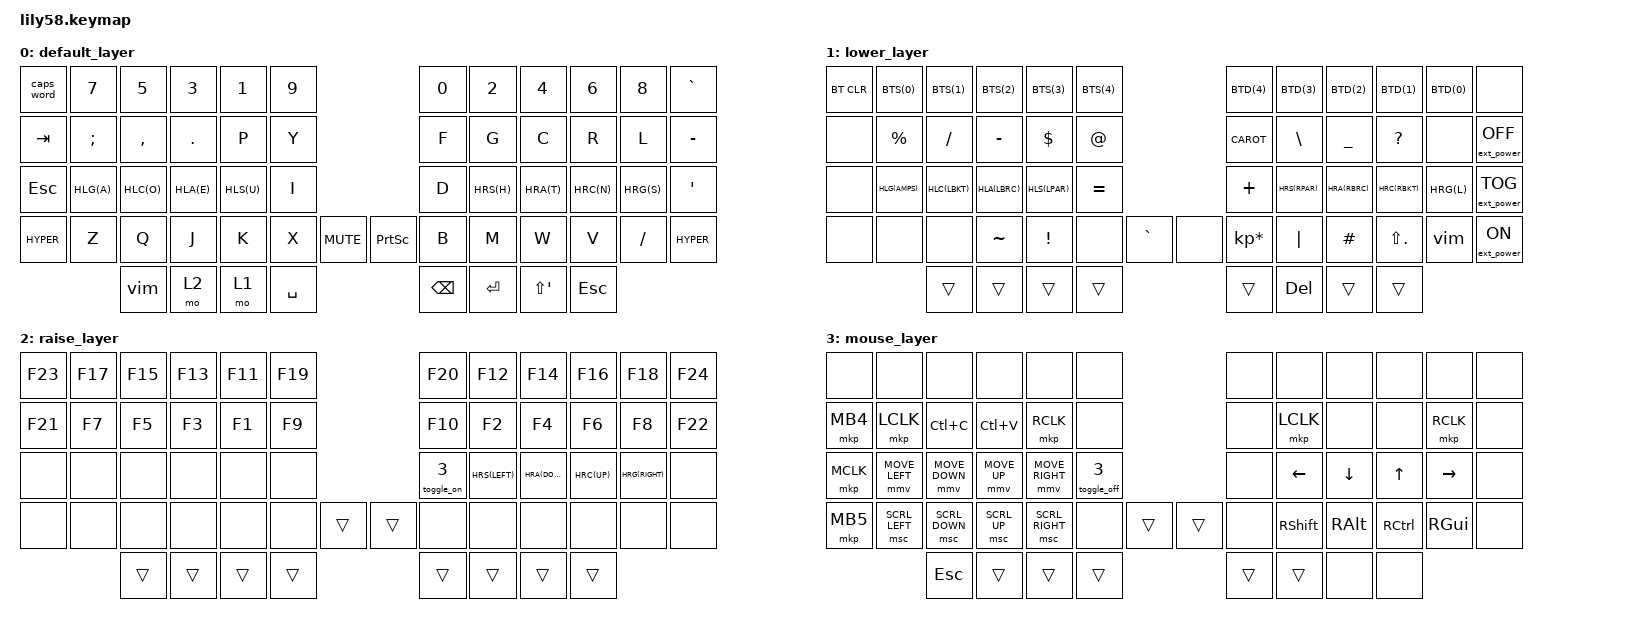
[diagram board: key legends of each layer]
#include <behaviors.dtsi>
#include <input/processors.dtsi>
#include <behaviors/input_gestures_accel.dtsi>

#define ZMK_POINTING_DEFAULT_MOVE_VAL 700  // default: 600
#define ZMK_POINTING_DEFAULT_SCRL_VAL 25    // default: 10

/**/
#include <dt-bindings/zmk/pointing.h>
#include <dt-bindings/zmk/bt.h>
#include <dt-bindings/zmk/ext_power.h>
#include <dt-bindings/zmk/keys.h>

#define CAROT CARET
#define HYPER LC(LS(LA(LGUI)))
#define HY(X) LC(LS(LA(LG(X))))

#define TT 250
#define QT 150

#define MULT &kp KP_MULTIPLY
#define LARR &kp LS(PERIOD)

/ {
    sensors {
        compatible = "zmk,keymap-sensors";
        sensors = <&left_encoder &right_encoder>;
        triggers-per-rotation = <20>;
    };
};

&led_strip { chain-length = <37>; };

&nice_view_spi { cs-gpios = <&pro_micro 4 GPIO_ACTIVE_HIGH>; };

&pointer_accel {
    input-type = <INPUT_EV_REL>;
    min-factor = <700>;
    max-factor = <4000>;
    speed-threshold = <500>;
    speed-max = <6000>;
    acceleration-exponent = <2>;
    track-remainders;
};

&mmv_input_listener {
    input-processors = <&pointer_accel>;
};


/ {
    behaviors {
        home_row_left: home_row_left {
            compatible = "zmk,behavior-hold-tap";
            label = "HOME_ROW_LEFT";
            bindings = <&kp>, <&kp>;

            #binding-cells = <2>;
            flavor = "tap-preferred";
            hold-trigger-key-positions = <6 7 8 9 10 11 23 22 21 20 19 18 30 31 32 34 33 35 48 49 47 46 45 44 43 54 55 56 57>;
            quick-tap-ms = <QT>;
            tapping-term-ms = <TT>;
        };

        home_row_right: home_row_right {
            compatible = "zmk,behavior-hold-tap";
            label = "HOME_ROW_RIGHT";
            bindings = <&kp>, <&kp>;
            #binding-cells = <2>;
            flavor = "tap-preferred";
            quick-tap-ms = <QT>;
            tapping-term-ms = <TT>;
            hold-trigger-key-positions = <5 4 3 2 1 0 12 14 13 15 16 17 29 42 41 40 39 37 38 36 24 25 26 27 28 50 51 52 53>;
        };


        toggle_on: toggle_on {
          compatible = "zmk,behavior-toggle-layer";
          #binding-cells = <1>;
          display-name = "Toggle On";
          toggle-mode = "on";
        };

        toggle_off: toggle_off {
          compatible = "zmk,behavior-toggle-layer";
          #binding-cells = <1>;
          display-name = "Toggle Off";
          toggle-mode = "off";
        };

    };

    macros {
      vim: vim {
            compatible = "zmk,behavior-macro";
            label = "VIM";
            #binding-cells = <0>;
            bindings = <&macro_press &kp LCTRL>, <&macro_tap &kp BSLH &kp N>, <&macro_release &kp LCTRL>;
        };

    };

    combos {
        compatible = "zmk,combos";
        combo_rptl {
            timeout-ms = <150>;
            key-positions = <14 15 16>;
            bindings = <&key_repeat>;
            layers = <0 1 2>;
        };
        combo_rptr {
            timeout-ms = <150>;
            key-positions = <19 20 21>;
            bindings = <&key_repeat>;
            layers = <0 1 2>;
        };
    };

#define HLG(KEY) &home_row_left LGUI KEY
#define HLC(KEY) &home_row_left LCTRL KEY
#define HLA(KEY) &home_row_left LALT KEY
#define HLS(KEY) &home_row_left LSHIFT KEY

#define HRG(KEY) &home_row_right RGUI KEY
#define HRC(KEY) &home_row_right RCTRL KEY
#define HRA(KEY) &home_row_right RALT KEY
#define HRS(KEY) &home_row_right RSHIFT KEY

    keymap {
        compatible = "zmk,keymap";

        default_layer {
            bindings = <
&caps_word &kp N7   &kp N5    &kp N3     &kp N1  &kp N9                         &kp N0  &kp N2  &kp N4  &kp N6  &kp N8   &kp GRAVE
&kp TAB    &kp SEMI &kp COMMA &kp PERIOD &kp P   &kp Y                          &kp F   &kp G   &kp C   &kp R   &kp L    &kp MINUS
&kp ESCAPE HLG(A)   HLC(O)    HLA(E)     HLS(U)  &kp I                          &kp D   HRS(H)  HRA(T)  HRC(N)  HRG(S)   &kp SQT
&kp HYPER  &kp Z    &kp Q     &kp J      &kp K   &kp X   &kp C_MUTE   &kp PSCRN &kp B   &kp M   &kp W   &kp V   &kp FSLH &kp HYPER
                    &vim      &mo 2      &mo 1   &kp SPACE                     &kp BSPC &kp RET &kp LS(SQT) &kp ESCAPE
            >;

            sensor-bindings = <
                        &inc_dec_kp HY(C_VOL_UP) HY(C_VOL_DN)
                        &inc_dec_kp HY(C_BRI_INC) HY(C_BRI_DEC)
            >;
        };

        lower_layer {
#define BTS(N) &bt BT_SEL N
#define BTD(N) &bt BT_DISC N

            bindings = <
&bt BT_CLR BTS(0)    BTS(1)    BTS(2)    BTS(3)     BTS(4)                     BTD(4)    BTD(3)    BTD(2)    BTD(1)    BTD(0) &none
&none      &kp PRCNT &kp FSLH  &kp MINUS &kp DOLLAR &kp AT                     &kp CAROT &kp BSLH  &kp UNDER &kp QMARK &none  &ext_power EP_OFF
&none      HLG(AMPS) HLC(LBKT) HLA(LBRC) HLS(LPAR)  &kp EQUAL                  &kp PLUS  HRS(RPAR) HRA(RBRC) HRC(RBKT) HRG(L) &ext_power EP_TOG
&none      &none     &none     &kp TILDE  &kp EXCL  &none     &kp GRAVE &none  MULT      &kp PIPE  &kp POUND LARR      &vim   &ext_power EP_ON
                     &trans    &trans     &trans    &trans                     &trans    &kp DEL   &trans    &trans
            >;

            sensor-bindings = <
                        &inc_dec_kp C_VOL_UP C_VOL_DN
                        &inc_dec_kp PG_UP PG_DN
            >;
        };

        raise_layer {
            bindings = <
&kp F23    &kp F17 &kp F15 &kp F13  &kp F11  &kp F19                    &kp F20      &kp F12    &kp F14    &kp F16   &kp F18    &kp F24
&kp F21    &kp F7  &kp F5  &kp F3   &kp F1   &kp F9                     &kp F10      &kp F2     &kp F4     &kp F6    &kp F8     &kp F22
&none      &none   &none   &none    &none    &none                      &toggle_on 3 HRS(LEFT)  HRA(DOWN)  HRC(UP)   HRG(RIGHT) &none
&none      &none   &none   &none    &none    &none    &trans    &trans  &none        &none      &none      &none     &none      &none
                           &trans   &trans   &trans   &trans    &trans  &trans       &trans     &trans
            >;

            sensor-bindings = <
                        &inc_dec_kp C_VOL_UP C_VOL_DN
                        &inc_dec_kp PG_UP PG_DN
            >;
        };

        mouse_layer {
            bindings = <
&none      &none            &none            &none           &none              &none                      &none        &none      &none      &none     &none      &none
&mkp MB4   &mkp LCLK        &kp LC(C)        &kp LC(V)       &mkp RCLK          &none                      &none        &mkp LCLK  &none      &none     &mkp RCLK  &none
&mkp MCLK  &mmv MOVE_LEFT   &mmv MOVE_DOWN   &mmv MOVE_UP    &mmv MOVE_RIGHT    &toggle_off 3              &none        &kp LEFT   &kp DOWN   &kp UP    &kp RIGHT  &none
&mkp MB5   &msc SCRL_LEFT   &msc SCRL_DOWN   &msc SCRL_UP    &msc SCRL_RIGHT    &none    &trans    &trans  &none        &kp RSHFT  &kp RALT   &kp RCTRL &kp RGUI   &none
                                             &kp ESC         &trans             &trans   &trans    &trans  &trans       &none     &none
            >;

            sensor-bindings = <
                        &inc_dec_kp MOVE_LEFT MOVE_RIGHT
                        &inc_dec_kp MOVE_DOWN MOVE_UP
            >;
        };
    };
};

